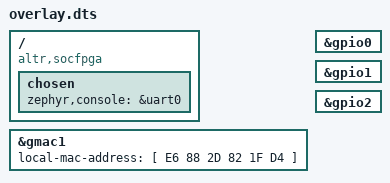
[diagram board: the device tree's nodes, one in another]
/ {
	compatible = "altr,socfpga", "altr,socfpga-cyclonev", "altr,socfpga-cyclonev-socdk";
	chosen {
		zephyr,console = &uart0;
	};
};
&gmac1{
	status = "okay";
	local-mac-address = [ E6 88 2D 82 1F D4 ];
};
&gpio0{
	status = "okay";
};
&gpio1{
	status = "okay";
};
&gpio2{
	status = "okay";
};
